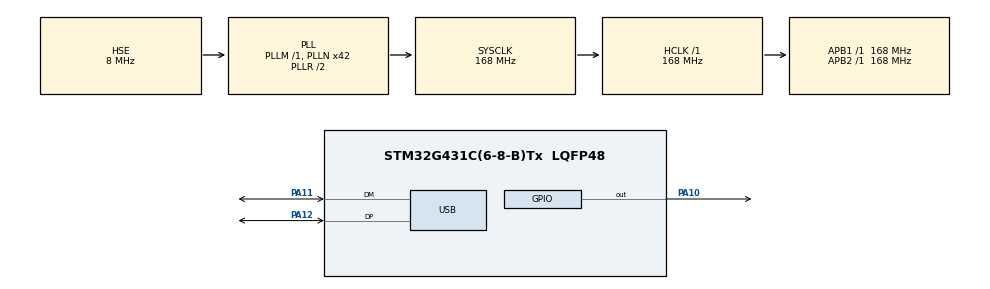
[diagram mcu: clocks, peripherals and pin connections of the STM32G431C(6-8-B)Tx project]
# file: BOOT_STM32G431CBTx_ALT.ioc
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Mcu.Family=STM32G4
Mcu.Name=STM32G431C(6-8-B)Tx
Mcu.Package=LQFP48
NVIC.PriorityGroup=NVIC_PRIORITYGROUP_4
NVIC.USB_LP_IRQn=true\:0\:0\:false\:false\:true\:false\:true\:true
PA10.Signal=GPIO_Output
PA11.Mode=Device
PA11.Signal=USB_DM
PA12.Mode=Device
PA12.Signal=USB_DP
PA13.Mode=Serial_Wire
PA13.Signal=SYS_JTMS-SWDIO
PA14.Mode=Serial_Wire
PA14.Signal=SYS_JTCK-SWCLK
PC14-OSC32_IN.Mode=LSE-External-Oscillator
PC14-OSC32_IN.Signal=RCC_OSC32_IN
PC15-OSC32_OUT.Mode=LSE-External-Oscillator
PC15-OSC32_OUT.Signal=RCC_OSC32_OUT
PF0-OSC_IN.Mode=HSE-External-Oscillator
PF0-OSC_IN.Signal=RCC_OSC_IN
PF1-OSC_OUT.Mode=HSE-External-Oscillator
PF1-OSC_OUT.Signal=RCC_OSC_OUT
ProjectManager.HeapSize=0x200
ProjectManager.StackSize=0x400
ProjectManager.TargetToolchain=MDK-ARM V5.32
RCC.ADC12Freq_Value=168000000
RCC.AHBFreq_Value=168000000
RCC.APB1Freq_Value=168000000
RCC.APB1TimFreq_Value=168000000
RCC.APB2Freq_Value=168000000
RCC.APB2TimFreq_Value=168000000
RCC.CK48CLockSelection=RCC_USBCLKSOURCE_HSI48
RCC.CortexFreq_Value=168000000
RCC.EXTERNAL_CLOCK_VALUE=12288000
RCC.HCLKFreq_Value=168000000
RCC.HSE_VALUE=8000000
RCC.HSI48_VALUE=48000000
RCC.HSI_VALUE=16000000
RCC.PLLN=42
RCC.PLLSourceVirtual=RCC_PLLSOURCE_HSE
RCC.SYSCLKFreq_VALUE=168000000
RCC.SYSCLKSource=RCC_SYSCLKSOURCE_PLLCLK
RCC.USBFreq_Value=48000000
RCC.VCOOutputFreq_Value=336000000
USB_DEVICE.CLASS_NAME_FS=CUSTOM_HID
USB_DEVICE.CUSTOM_HID_FS_BINTERVAL=1
USB_DEVICE.PID_CUSTOMHID_FS=0x573c
USB_DEVICE.USBD_CUSTOMHID_OUTREPORT_BUF_SIZE=64
USB_DEVICE.USBD_CUSTOM_HID_REPORT_DESC_SIZE=34
USB_DEVICE.USBD_LPM_ENABLED=0
USB_DEVICE.VID=0x462
USB_DEVICE.VirtualMode=CustomHid
USB_DEVICE.VirtualModeFS=Custom_Hid_FS
VP_SYS_VS_DBSignals.Mode=DisableDeadBatterySignals
VP_USB_DEVICE_VS_USB_DEVICE_CUSTOM_HID_FS.Mode=CUSTOM_HID_FS
board=custom

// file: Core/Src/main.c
/* USER CODE BEGIN Header */
/**
  ******************************************************************************
  * @file           : main.c
  * @brief          : Main program body
  ******************************************************************************
  * @attention
  *
  * Copyright (c) 2025 STMicroelectronics.
  * All rights reserved.
  *
  * This software is licensed under terms that can be found in the LICENSE file
  * in the root directory of this software component.
  * If no LICENSE file comes with this software, it is provided AS-IS.
  *
  ******************************************************************************
  */
/* USER CODE END Header */
#include "main.h"
#include "usb_device.h"

/* USER CODE BEGIN Includes */
#include "lpp_sdk_boot.h"
#include "counter.h"

/* USER CODE END Includes */

/* USER CODE BEGIN PM */

// ============================================================================
// Сигнатура и версия прошивки (APP)
// ============================================================================
const uint32_t BOOT_KEY0   __attribute__((section(BOOT_KEY0_SECTION)))   = BOOT_SIG_KEY0;
const uint32_t BOOT_KEY1   __attribute__((section(BOOT_KEY1_SECTION)))   = BOOT_SIG_KEY1;
const uint32_t BOOT_KEY2   __attribute__((section(BOOT_KEY2_SECTION)))   = BOOT_SIG_KEY2;
const uint32_t BOOT_KEY3   __attribute__((section(BOOT_KEY3_SECTION)))   = BOOT_SIG_KEY3;

const uint32_t BOOT_VER_F  __attribute__((section(BOOT_VER_F_SECTION)))  = BOOT_VERSION;

/* USER CODE END PM */

void SystemClock_Config(void);
static void MX_GPIO_Init(void);

int main(void)
{

  /* MCU Configuration--------------------------------------------------------*/

  /* Reset of all peripherals, Initializes the Flash interface and the Systick. */
  HAL_Init();

  /* Configure the system clock */
  SystemClock_Config();

  /* Initialize all configured peripherals */
  MX_GPIO_Init();
  MX_USB_Device_Init();
  /* USER CODE BEGIN 2 */

	// Инициализация USB
	USB->BCDR &= ~USB_BCDR_DPPU;  // DPPU = 0 → подтяжка DP отключена
//	HAL_GPIO_WritePin(GPIOA, GPIO_PIN_10, GPIO_PIN_RESET);  // Выключение USB
	HAL_Delay(2000);
//	HAL_GPIO_WritePin(GPIOA, GPIO_PIN_10, GPIO_PIN_SET);    // Включение USB
    USB->BCDR |= USB_BCDR_DPPU; // DPPU = 1 → подтяжка DP включена

  /* USER CODE END 2 */

  /* Infinite loop */
  while (1)
  {

  }
}

void SystemClock_Config(void)
{
  RCC_OscInitTypeDef RCC_OscInitStruct = {0};
  RCC_ClkInitTypeDef RCC_ClkInitStruct = {0};

  /** Configure the main internal regulator output voltage
  */
  HAL_PWREx_ControlVoltageScaling(PWR_REGULATOR_VOLTAGE_SCALE1_BOOST);

  /** Initializes the RCC Oscillators according to the specified parameters
  * in the RCC_OscInitTypeDef structure.
  */
  RCC_OscInitStruct.OscillatorType = RCC_OSCILLATORTYPE_HSI48|RCC_OSCILLATORTYPE_HSE;
  RCC_OscInitStruct.HSEState = RCC_HSE_ON;
  RCC_OscInitStruct.HSI48State = RCC_HSI48_ON;
  RCC_OscInitStruct.PLL.PLLState = RCC_PLL_ON;
  RCC_OscInitStruct.PLL.PLLSource = RCC_PLLSOURCE_HSE;
  RCC_OscInitStruct.PLL.PLLM = RCC_PLLM_DIV1;
  RCC_OscInitStruct.PLL.PLLN = 42;
  RCC_OscInitStruct.PLL.PLLP = RCC_PLLP_DIV2;
  RCC_OscInitStruct.PLL.PLLQ = RCC_PLLQ_DIV2;
  RCC_OscInitStruct.PLL.PLLR = RCC_PLLR_DIV2;
  if (HAL_RCC_OscConfig(&RCC_OscInitStruct) != HAL_OK)
  {
    Error_Handler();
  }

  /** Initializes the CPU, AHB and APB buses clocks
  */
  RCC_ClkInitStruct.ClockType = RCC_CLOCKTYPE_HCLK|RCC_CLOCKTYPE_SYSCLK
                              |RCC_CLOCKTYPE_PCLK1|RCC_CLOCKTYPE_PCLK2;
  RCC_ClkInitStruct.SYSCLKSource = RCC_SYSCLKSOURCE_PLLCLK;
  RCC_ClkInitStruct.AHBCLKDivider = RCC_SYSCLK_DIV1;
  RCC_ClkInitStruct.APB1CLKDivider = RCC_HCLK_DIV1;
  RCC_ClkInitStruct.APB2CLKDivider = RCC_HCLK_DIV1;

  if (HAL_RCC_ClockConfig(&RCC_ClkInitStruct, FLASH_LATENCY_4) != HAL_OK)
  {
    Error_Handler();
  }
}

static void MX_GPIO_Init(void)
{
  GPIO_InitTypeDef GPIO_InitStruct = {0};

  /* GPIO Ports Clock Enable */
  __HAL_RCC_GPIOC_CLK_ENABLE();
  __HAL_RCC_GPIOF_CLK_ENABLE();
  __HAL_RCC_GPIOA_CLK_ENABLE();

  /*Configure GPIO pin Output Level */
  HAL_GPIO_WritePin(GPIOA, GPIO_PIN_10, GPIO_PIN_RESET);

  /*Configure GPIO pin : PA10 */
  GPIO_InitStruct.Pin = GPIO_PIN_10;
  GPIO_InitStruct.Mode = GPIO_MODE_OUTPUT_PP;
  GPIO_InitStruct.Pull = GPIO_NOPULL;
  GPIO_InitStruct.Speed = GPIO_SPEED_FREQ_LOW;
  HAL_GPIO_Init(GPIOA, &GPIO_InitStruct);

}

/* USER CODE BEGIN 4 */

// ============================================================================
// Отправка 64-байтного пакета хосту (используется SDK)
// ============================================================================
extern uint8_t USBD_CUSTOM_HID_SendReport(USBD_HandleTypeDef* pdev, uint8_t* report, uint16_t len);
extern USBD_HandleTypeDef hUsbDeviceFS;

uint8_t PacketSend(uint8_t* buffer)
{
    // Отправка HID отчёта (64 байта)
    return USBD_CUSTOM_HID_SendReport(&hUsbDeviceFS, buffer, 64);
}

/* USER CODE END 4 */

void Error_Handler(void)
{
  __disable_irq();
  while (1)
  {
  }
}
